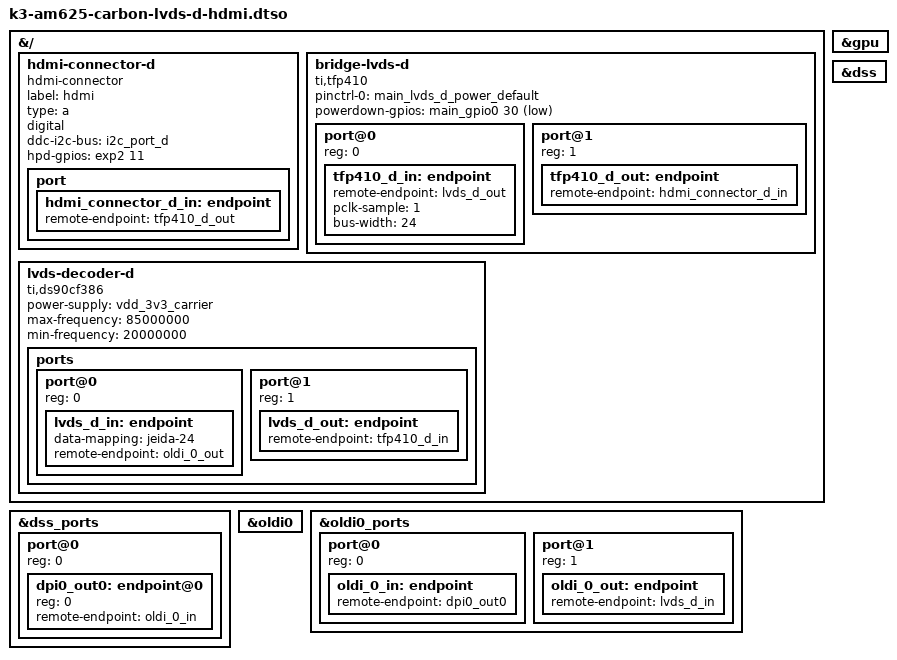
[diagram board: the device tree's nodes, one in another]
// SPDX-License-Identifier: GPL-2.0-only OR MIT
/*
 * LVDS D to HDMI Expansion Board for Carbon AM62x
 *
 * Copyright (C) 2024 Ezurio LLC
 */

/dts-v1/;
/plugin/;

#include <dt-bindings/gpio/gpio.h>
#include "k3-pinctrl.h"

&{/} {
	hdmi-connector-d {
		compatible = "hdmi-connector";
		label = "hdmi";
		type = "a";
		digital;

		/* For miswired U3 VDD_5V */
		//pinctrl-names = "default";
		//pinctrl-0 = <&main_lvds_d_power_default>;
		//ddc-en-gpios = <&main_gpio0 30 GPIO_ACTIVE_HIGH>;

		ddc-i2c-bus = <&i2c_port_d>;

		hpd-gpios = <&exp2 11 GPIO_ACTIVE_HIGH>;

		port {
			hdmi_connector_d_in: endpoint {
				remote-endpoint = <&tfp410_d_out>;
			};
		};
	};

	bridge-lvds-d {
		#address-cells = <1>;
		#size-cells = <0>;
		compatible = "ti,tfp410";

		pinctrl-names = "default";
		pinctrl-0 = <&main_lvds_d_power_default>;
		powerdown-gpios = <&main_gpio0 30 GPIO_ACTIVE_LOW>;

		port@0 {
			reg = <0>;

			tfp410_d_in: endpoint {
				remote-endpoint = <&lvds_d_out>;
				pclk-sample = <1>;
				bus-width = <24>;
			};
		};

		port@1 {
			reg = <1>;

			tfp410_d_out: endpoint {
				remote-endpoint = <&hdmi_connector_d_in>;
			};
		};
	};

	lvds-decoder-d {
		compatible = "ti,ds90cf386", "lvds-decoder";

		power-supply = <&vdd_3v3_carrier>;

		max-frequency = <85000000>;
		min-frequency = <20000000>;

		ports {
			#address-cells = <1>;
			#size-cells = <0>;

			port@0 {
				reg = <0>;
				lvds_d_in: endpoint {
					data-mapping = "jeida-24";
					remote-endpoint = <&oldi_0_out>;
				};
			};

			port@1 {
				reg = <1>;
				lvds_d_out: endpoint {
					remote-endpoint = <&tfp410_d_in>;
				};
			};
		};
	};
};

&gpu {
	status = "okay";
};

&dss {
	status = "okay";
};

&dss_ports {
	#address-cells = <1>;
	#size-cells = <0>;

	/* Video Port 1 Output to OLDI */
	port@0 {
		reg = <0>;
		#address-cells = <1>;
		#size-cells = <0>;

		dpi0_out0: endpoint@0 {
			reg = <0>;
			remote-endpoint = <&oldi_0_in>;
		};
	};
};

&oldi0 {
	status = "okay";
};

&oldi0_ports {
	#address-cells = <1>;
	#size-cells = <0>;

	port@0 {
		reg = <0>;

		oldi_0_in: endpoint {
			remote-endpoint = <&dpi0_out0>;
		};
	};

	port@1 {
		reg = <1>;

		oldi_0_out: endpoint {
			remote-endpoint = <&lvds_d_in>;
		};
	};
};
